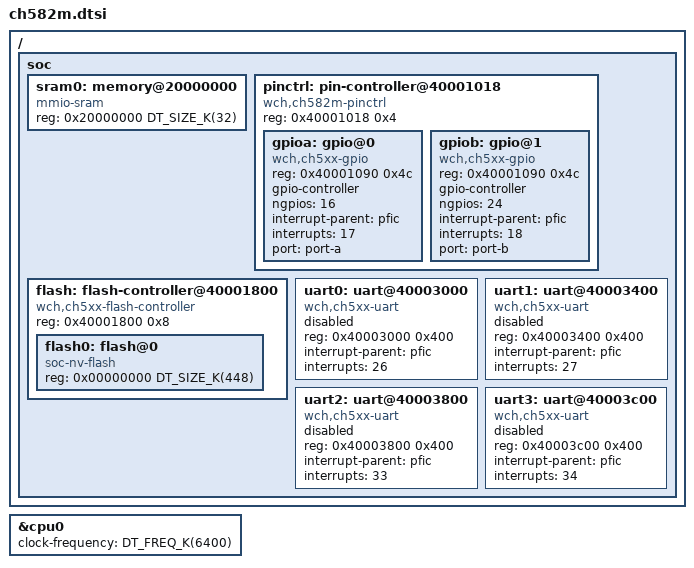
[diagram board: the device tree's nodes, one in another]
/*
 * SPDX-FileCopyrightText: Copyright The Zephyr Project Contributors
 * SPDX-License-Identifier: Apache-2.0
 */

#include <freq.h>
#include <mem.h>
#include <wch/qingke-v4a.dtsi>

/ {
	soc {
		sram0: memory@20000000 {
			compatible = "mmio-sram";
			reg = <0x20000000 DT_SIZE_K(32)>;
		};

		pinctrl: pin-controller@40001018 {
			compatible = "wch,ch582m-pinctrl";
			reg = <0x40001018 0x4>;
			#address-cells = <1>;
			#size-cells = <1>;

			gpioa: gpio@0 {
				compatible = "wch,ch5xx-gpio";
				reg = <0x40001090 0x4c>;
				gpio-controller;
				#gpio-cells = <2>;
				ngpios = <16>;
				interrupt-parent = <&pfic>;
				interrupts = <17>;
				port = "port-a";
			};

			gpiob: gpio@1 {
				compatible = "wch,ch5xx-gpio";
				reg = <0x40001090 0x4c>;
				gpio-controller;
				#gpio-cells = <2>;
				ngpios = <24>;
				interrupt-parent = <&pfic>;
				interrupts = <18>;
				port = "port-b";
			};
		};

		flash: flash-controller@40001800 {
			compatible = "wch,ch5xx-flash-controller";
			reg = <0x40001800 0x8>;
			ranges;

			#address-cells = <1>;
			#size-cells = <1>;

			flash0: flash@0 {
				compatible = "soc-nv-flash";
				reg = <0x00000000 DT_SIZE_K(448)>;
				ranges = <0x0 0x00000000 DT_SIZE_K(448)>;

				#address-cells = <1>;
				#size-cells = <1>;
			};
		};

		uart0: uart@40003000 {
			compatible = "wch,ch5xx-uart";
			reg = <0x40003000 0x400>;
			interrupt-parent = <&pfic>;
			interrupts = <26>;
			status = "disabled";
		};

		uart1: uart@40003400 {
			compatible = "wch,ch5xx-uart";
			reg = <0x40003400 0x400>;
			interrupt-parent = <&pfic>;
			interrupts = <27>;
			status = "disabled";
		};

		uart2: uart@40003800 {
			compatible = "wch,ch5xx-uart";
			reg = <0x40003800 0x400>;
			interrupt-parent = <&pfic>;
			interrupts = <33>;
			status = "disabled";
		};

		uart3: uart@40003c00 {
			compatible = "wch,ch5xx-uart";
			reg = <0x40003c00 0x400>;
			interrupt-parent = <&pfic>;
			interrupts = <34>;
			status = "disabled";
		};
	};
};

&cpu0 {
	/* Default system clock after reset: 32MHz / 5 (see R32_CLOCK_CONFIG) */
	clock-frequency = <DT_FREQ_K(6400)>;
};
